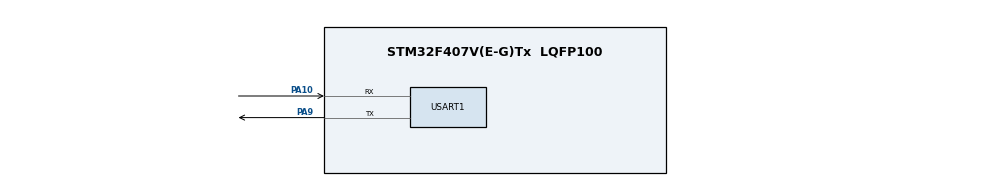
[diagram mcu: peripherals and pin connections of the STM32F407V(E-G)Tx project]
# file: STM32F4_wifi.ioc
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Mcu.Family=STM32F4
Mcu.Name=STM32F407V(E-G)Tx
Mcu.Package=LQFP100
NVIC.PriorityGroup=NVIC_PRIORITYGROUP_4
PA10.Mode=Asynchronous
PA10.Signal=USART1_RX
PA9.Mode=Asynchronous
PA9.Signal=USART1_TX
ProjectManager.TargetToolchain=TrueSTUDIO
RCC.48MHZClocksFreq_Value=48000000
RCC.AHBFreq_Value=16000000
RCC.APB1Freq_Value=16000000
RCC.APB2Freq_Value=16000000
RCC.CortexFreq_Value=16000000
RCC.HSE_VALUE=25000000
RCC.HSI_VALUE=16000000
RCC.LSE_VALUE=32768
RCC.SYSCLKFreq_VALUE=16000000
RCC.VCOOutputFreq_Value=192000000
board=custom

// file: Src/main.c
/**
  ******************************************************************************
  * File Name          : main.c
  * Description        : Main program body
  ******************************************************************************
  *
  * COPYRIGHT(c) 2015 STMicroelectronics
  *
  * Redistribution and use in source and binary forms, with or without modification,
  * are permitted provided that the following conditions are met:
  *   1. Redistributions of source code must retain the above copyright notice,
  *      this list of conditions and the following disclaimer.
  *   2. Redistributions in binary form must reproduce the above copyright notice,
  *      this list of conditions and the following disclaimer in the documentation
  *      and/or other materials provided with the distribution.
  *   3. Neither the name of STMicroelectronics nor the names of its contributors
  *      may be used to endorse or promote products derived from this software
  *      without specific prior written permission.
  *
  * THIS SOFTWARE IS PROVIDED BY THE COPYRIGHT HOLDERS AND CONTRIBUTORS "AS IS"
  * AND ANY EXPRESS OR IMPLIED WARRANTIES, INCLUDING, BUT NOT LIMITED TO, THE
  * IMPLIED WARRANTIES OF MERCHANTABILITY AND FITNESS FOR A PARTICULAR PURPOSE ARE
  * DISCLAIMED. IN NO EVENT SHALL THE COPYRIGHT HOLDER OR CONTRIBUTORS BE LIABLE
  * FOR ANY DIRECT, INDIRECT, INCIDENTAL, SPECIAL, EXEMPLARY, OR CONSEQUENTIAL
  * DAMAGES (INCLUDING, BUT NOT LIMITED TO, PROCUREMENT OF SUBSTITUTE GOODS OR
  * SERVICES; LOSS OF USE, DATA, OR PROFITS; OR BUSINESS INTERRUPTION) HOWEVER
  * CAUSED AND ON ANY THEORY OF LIABILITY, WHETHER IN CONTRACT, STRICT LIABILITY,
  * OR TORT (INCLUDING NEGLIGENCE OR OTHERWISE) ARISING IN ANY WAY OUT OF THE USE
  * OF THIS SOFTWARE, EVEN IF ADVISED OF THE POSSIBILITY OF SUCH DAMAGE.
  *
  ******************************************************************************
  */

#include "stm32f4xx_hal.h"

UART_HandleTypeDef huart1;

void SystemClock_Config(void);
static void MX_GPIO_Init(void);
static void MX_USART1_UART_Init(void);

int main(void)
{

  /* MCU Configuration----------------------------------------------------------*/

  /* Reset of all peripherals, Initializes the Flash interface and the Systick. */
  HAL_Init();

  /* Configure the system clock */
  SystemClock_Config();

  /* Initialize all configured peripherals */
  MX_GPIO_Init();
  MX_USART1_UART_Init();

  /* USER CODE BEGIN 2 */
  //UART initialized
  HAL_UART_Transmit(huart1, uint8_t *pData, uint16_t Size, uint32_t Timeout);//TODO transmit test command

  /* USER CODE END 2 */

  /* Infinite loop */
  while (1)
  {

  }

}

/** System Clock Configuration
*/
void SystemClock_Config(void)
{

  RCC_OscInitTypeDef RCC_OscInitStruct;

  __PWR_CLK_ENABLE();

  __HAL_PWR_VOLTAGESCALING_CONFIG(PWR_REGULATOR_VOLTAGE_SCALE2);

  RCC_OscInitStruct.OscillatorType = RCC_OSCILLATORTYPE_HSI;
  RCC_OscInitStruct.HSIState = RCC_HSI_ON;
  RCC_OscInitStruct.HSICalibrationValue = 16;
  RCC_OscInitStruct.PLL.PLLState = RCC_PLL_NONE;
  HAL_RCC_OscConfig(&RCC_OscInitStruct);

  HAL_SYSTICK_Config(HAL_RCC_GetHCLKFreq()/1000);

  HAL_SYSTICK_CLKSourceConfig(SYSTICK_CLKSOURCE_HCLK);

}

/* USART1 init function */
void MX_USART1_UART_Init(void)
{

  huart1.Instance = USART1;
  huart1.Init.BaudRate = 115200;	//baud rate is correct, can also use 9600
  huart1.Init.WordLength = UART_WORDLENGTH_8B;
  huart1.Init.StopBits = UART_STOPBITS_1;
  huart1.Init.Parity = UART_PARITY_NONE;
  huart1.Init.Mode = UART_MODE_TX_RX;
  huart1.Init.HwFlowCtl = UART_HWCONTROL_NONE;
  huart1.Init.OverSampling = UART_OVERSAMPLING_16;
  HAL_UART_Init(&huart1);

}

/** Pinout Configuration
*/
void MX_GPIO_Init(void)
{

  /* GPIO Ports Clock Enable */
  __GPIOA_CLK_ENABLE();

}

/************************ (C) COPYRIGHT STMicroelectronics *****END OF FILE****/
